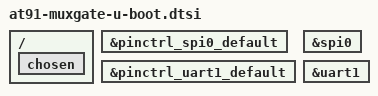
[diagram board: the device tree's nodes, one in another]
/*
 * at91-muxgate-u-boot.dtsi – Device Tree include for Thorsis Technologies MUXgate board
 *
 * © 2023 Thorsis Technologies GmbH
 */

/ {
	chosen {
		bootph-all;
	};
};

&pinctrl_spi0_default {
	bootph-all;
};

&pinctrl_uart1_default {
	bootph-all;
};

&spi0 {
	bootph-all;
};

&uart1 {
	bootph-all;
};
